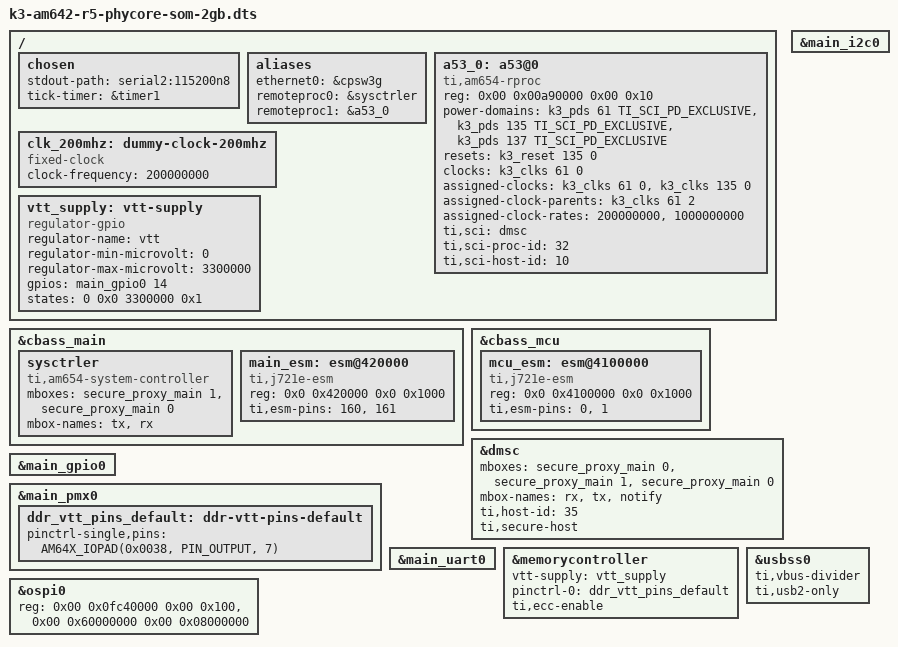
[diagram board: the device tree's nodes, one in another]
// SPDX-License-Identifier: GPL-2.0
/*
 * Copyright (C) 2021 PHYTEC America, LLC - https://www.phytec.com
 */

/dts-v1/;

#include "k3-am642-phyboard-electra-rdk.dts"
#include "k3-am64-phycore-som-ddr4-2gb.dtsi"
#include "k3-am64-ddr.dtsi"

/ {
	chosen {
		stdout-path = "serial2:115200n8";
		tick-timer = &timer1;
	};

	aliases {
		ethernet0 = &cpsw3g;
		remoteproc0 = &sysctrler;
		remoteproc1 = &a53_0;
	};

	a53_0: a53@0 {
		compatible = "ti,am654-rproc";
		reg = <0x00 0x00a90000 0x00 0x10>;
		power-domains = <&k3_pds 61 TI_SCI_PD_EXCLUSIVE>,
				<&k3_pds 135 TI_SCI_PD_EXCLUSIVE>,
				<&k3_pds 137 TI_SCI_PD_EXCLUSIVE>;
		resets = <&k3_reset 135 0>;
		clocks = <&k3_clks 61 0>;
		assigned-clocks = <&k3_clks 61 0>, <&k3_clks 135 0>;
		assigned-clock-parents = <&k3_clks 61 2>;
		assigned-clock-rates = <200000000>, <1000000000>;
		ti,sci = <&dmsc>;
		ti,sci-proc-id = <32>;
		ti,sci-host-id = <10>;
		bootph-pre-ram;
	};

	clk_200mhz: dummy-clock-200mhz {
		compatible = "fixed-clock";
		#clock-cells = <0>;
		clock-frequency = <200000000>;
		bootph-pre-ram;
	};

	vtt_supply: vtt-supply {
		compatible = "regulator-gpio";
		regulator-name = "vtt";
		regulator-min-microvolt = <0>;
		regulator-max-microvolt = <3300000>;
		gpios = <&main_gpio0 14 GPIO_ACTIVE_HIGH>;
		states = <0 0x0 3300000 0x1>;
		bootph-pre-ram;
	};
};

&cbass_main {
	sysctrler: sysctrler {
		compatible = "ti,am654-system-controller";
		mboxes= <&secure_proxy_main 1>, <&secure_proxy_main 0>;
		mbox-names = "tx", "rx";
		bootph-pre-ram;
	};

	main_esm: esm@420000 {
		compatible = "ti,j721e-esm";
		reg = <0x0 0x420000 0x0 0x1000>;
		ti,esm-pins = <160>, <161>;
		bootph-pre-ram;
	};
};

&cbass_mcu {
	bootph-pre-ram;
	mcu_esm: esm@4100000 {
		compatible = "ti,j721e-esm";
		reg = <0x0 0x4100000 0x0 0x1000>;
		ti,esm-pins = <0>, <1>;
		bootph-pre-ram;
	};
};

&dmsc {
	mboxes= <&secure_proxy_main 0>,
		<&secure_proxy_main 1>,
		<&secure_proxy_main 0>;
	mbox-names = "rx", "tx", "notify";
	ti,host-id = <35>;
	ti,secure-host;
};

&main_gpio0 {
	/delete-property/ power-domains;
};

&main_i2c0 {
	/delete-property/ power-domains;
};

&main_pmx0 {
	bootph-pre-ram;
	ddr_vtt_pins_default: ddr-vtt-pins-default {
		bootph-pre-ram;
		pinctrl-single,pins = <
			AM64X_IOPAD(0x0038, PIN_OUTPUT, 7)	/* (L17) OSPI0_CSn3.GPIO0_14 */
		>;
	};
};

&main_uart0 {
	/delete-property/ power-domains;
	/delete-property/ clocks;
	/delete-property/ clock-names;
};

&memorycontroller {
	vtt-supply = <&vtt_supply>;
	pinctrl-names = "default";
	pinctrl-0 = <&ddr_vtt_pins_default>;
	ti,ecc-enable;
};

&ospi0 {
	reg = <0x00 0x0fc40000 0x00 0x100>,
	      <0x00 0x60000000 0x00 0x08000000>;
};

&usbss0 {
	ti,vbus-divider;
	ti,usb2-only;
};

#include "k3-am642-phyboard-electra-rdk-u-boot.dtsi"
